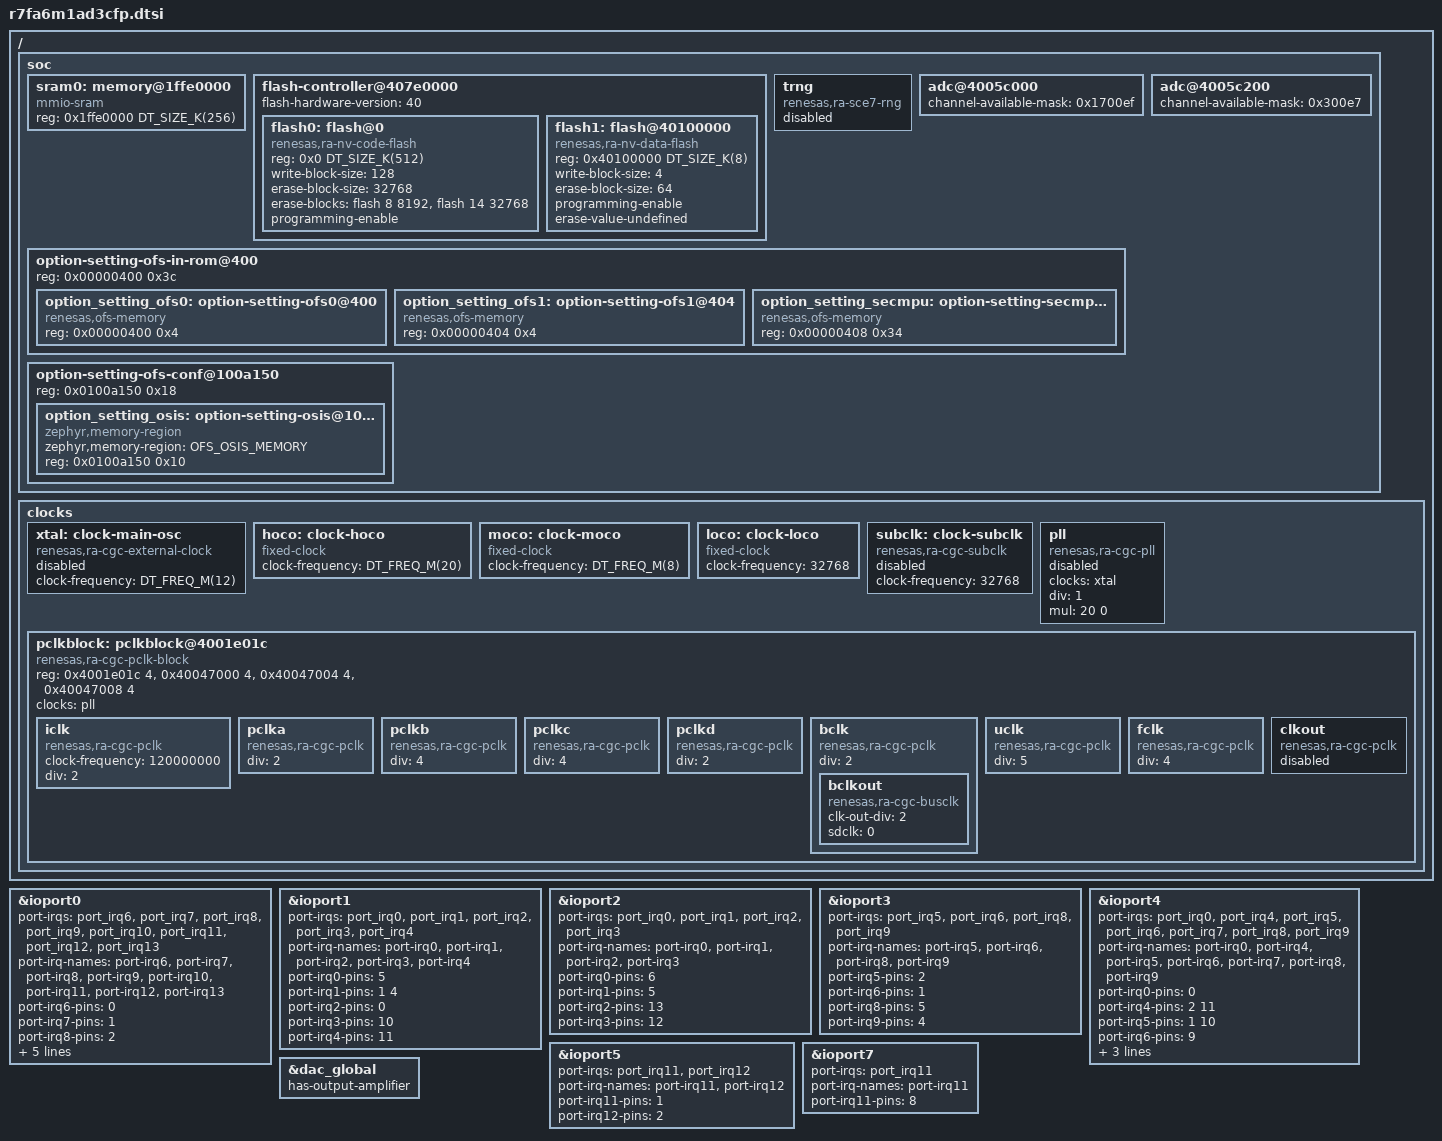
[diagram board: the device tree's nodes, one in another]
/*
 * Copyright (c) 2024-2025 Renesas Electronics Corporation
 *
 * SPDX-License-Identifier: Apache-2.0
 */

#include <zephyr/dt-bindings/clock/ra_clock.h>
#include <arm/renesas/ra/ra6/ra6-cm4-common.dtsi>
#include <zephyr/dt-bindings/misc/renesas/ra-elc/ra6m1-elc.h>

/delete-node/ &eth;
/delete-node/ &mdio;
/delete-node/ &qspi0;

/ {
	soc {
		sram0: memory@1ffe0000 {
			compatible = "mmio-sram";
			reg = <0x1ffe0000 DT_SIZE_K(256)>;
		};

		flash-controller@407e0000 {
			flash-hardware-version = <40>;
			#erase-block-cells = <2>;

			flash0: flash@0 {
				compatible = "renesas,ra-nv-code-flash";
				reg = <0x0 DT_SIZE_K(512)>;
				write-block-size = <128>;
				erase-block-size = <32768>;
				erase-blocks = <&flash 8 8192>, <&flash 14 32768>;
				programming-enable;
			};

			flash1: flash@40100000 {
				compatible = "renesas,ra-nv-data-flash";
				reg = <0x40100000 DT_SIZE_K(8)>;
				write-block-size = <4>;
				erase-block-size = <64>;
				programming-enable;
				erase-value-undefined;
			};
		};

		trng: trng {
			compatible = "renesas,ra-sce7-rng";
			status = "disabled";
		};

		adc@4005c000 {
			channel-available-mask = <0x1700ef>;
		};

		adc@4005c200 {
			channel-available-mask = <0x300e7>;
		};

		option-setting-ofs-in-rom@400 {
			reg = <0x00000400 0x3c>;
			#address-cells = <1>;
			#size-cells = <1>;

			option_setting_ofs0: option-setting-ofs0@400 {
				compatible = "renesas,ofs-memory";
				reg = <0x00000400 0x4>;
				status = "okay";
			};

			option_setting_ofs1: option-setting-ofs1@404 {
				compatible = "renesas,ofs-memory";
				reg = <0x00000404 0x4>;
				status = "okay";
			};

			option_setting_secmpu: option-setting-secmpu@408 {
				compatible = "renesas,ofs-memory";
				reg = <0x00000408 0x34>;
				status = "okay";
			};
		};

		option-setting-ofs-conf@100a150 {
			reg = <0x0100a150 0x18>;
			#address-cells = <1>;
			#size-cells = <1>;
			status = "okay";

			option_setting_osis: option-setting-osis@100a150 {
				compatible = "zephyr,memory-region";
				zephyr,memory-region = "OFS_OSIS_MEMORY";
				reg = <0x0100a150 0x10>;
				status = "okay";
			};
		};
	};

	clocks: clocks {
		#address-cells = <1>;
		#size-cells = <1>;

		xtal: clock-main-osc {
			compatible = "renesas,ra-cgc-external-clock";
			clock-frequency = <DT_FREQ_M(12)>;
			#clock-cells = <0>;
			status = "disabled";
		};

		hoco: clock-hoco {
			compatible = "fixed-clock";
			clock-frequency = <DT_FREQ_M(20)>;
			#clock-cells = <0>;
		};

		moco: clock-moco {
			compatible = "fixed-clock";
			clock-frequency = <DT_FREQ_M(8)>;
			#clock-cells = <0>;
		};

		loco: clock-loco {
			compatible = "fixed-clock";
			clock-frequency = <32768>;
			#clock-cells = <0>;
		};

		subclk: clock-subclk {
			compatible = "renesas,ra-cgc-subclk";
			clock-frequency = <32768>;
			#clock-cells = <0>;
			status = "disabled";
		};

		pll: pll {
			compatible = "renesas,ra-cgc-pll";
			#clock-cells = <0>;

			/* PLL */
			clocks = <&xtal>;
			div = <1>;
			mul = <20 0>;
			status = "disabled";
		};

		pclkblock: pclkblock@4001e01c {
			compatible = "renesas,ra-cgc-pclk-block";
			reg = <0x4001e01c 4>, <0x40047000 4>, <0x40047004 4>,
			      <0x40047008 4>;
			reg-names = "MSTPA", "MSTPB", "MSTPC",
				    "MSTPD";
			#clock-cells = <0>;
			clocks = <&pll>;
			status = "okay";

			iclk: iclk {
				compatible = "renesas,ra-cgc-pclk";
				clock-frequency = <120000000>;
				div = <2>;
				#clock-cells = <2>;
				status = "okay";
			};

			pclka: pclka {
				compatible = "renesas,ra-cgc-pclk";
				div = <2>;
				#clock-cells = <2>;
				status = "okay";
			};

			pclkb: pclkb {
				compatible = "renesas,ra-cgc-pclk";
				div = <4>;
				#clock-cells = <2>;
				status = "okay";
			};

			pclkc: pclkc {
				compatible = "renesas,ra-cgc-pclk";
				div = <4>;
				#clock-cells = <2>;
				status = "okay";
			};

			pclkd: pclkd {
				compatible = "renesas,ra-cgc-pclk";
				div = <2>;
				#clock-cells = <2>;
				status = "okay";
			};

			bclk: bclk {
				compatible = "renesas,ra-cgc-pclk";
				div = <2>;

				bclkout: bclkout {
					compatible = "renesas,ra-cgc-busclk";
					clk-out-div = <2>;
					sdclk = <0>;
					#clock-cells = <0>;
				};
				#clock-cells = <2>;
				status = "okay";
			};

			uclk: uclk {
				compatible = "renesas,ra-cgc-pclk";
				div = <5>;
				#clock-cells = <2>;
				status = "okay";
			};

			fclk: fclk {
				compatible = "renesas,ra-cgc-pclk";
				div = <4>;
				#clock-cells = <2>;
				status = "okay";
			};

			clkout: clkout {
				compatible = "renesas,ra-cgc-pclk";
				#clock-cells = <2>;
				status = "disabled";
			};
		};
	};
};

&ioport0 {
	port-irqs = <&port_irq6 &port_irq7 &port_irq8
		     &port_irq9 &port_irq10 &port_irq11
		     &port_irq12 &port_irq13>;
	port-irq-names = "port-irq6",
			 "port-irq7",
			 "port-irq8",
			 "port-irq9",
			 "port-irq10",
			 "port-irq11",
			 "port-irq12",
			 "port-irq13";
	port-irq6-pins = <0>;
	port-irq7-pins = <1>;
	port-irq8-pins = <2>;
	port-irq9-pins = <4>;
	port-irq10-pins = <5>;
	port-irq11-pins = <6>;
	port-irq12-pins = <8>;
	port-irq13-pins = <15>;
};

&ioport1 {
	port-irqs = <&port_irq0 &port_irq1 &port_irq2
		     &port_irq3 &port_irq4>;
	port-irq-names = "port-irq0",
			 "port-irq1",
			 "port-irq2",
			 "port-irq3",
			 "port-irq4";
	port-irq0-pins = <5>;
	port-irq1-pins = <1 4>;
	port-irq2-pins = <0>;
	port-irq3-pins = <10>;
	port-irq4-pins = <11>;
};

&ioport2 {
	port-irqs = <&port_irq0 &port_irq1 &port_irq2
		     &port_irq3>;
	port-irq-names = "port-irq0",
			 "port-irq1",
			 "port-irq2",
			 "port-irq3";
	port-irq0-pins = <6>;
	port-irq1-pins = <5>;
	port-irq2-pins = <13>;
	port-irq3-pins = <12>;
};

&ioport3 {
	port-irqs = <&port_irq5 &port_irq6
		     &port_irq8 &port_irq9>;
	port-irq-names = "port-irq5",
			 "port-irq6",
			 "port-irq8",
			 "port-irq9";
	port-irq5-pins = <2>;
	port-irq6-pins = <1>;
	port-irq8-pins = <5>;
	port-irq9-pins = <4>;
};

&ioport4 {
	port-irqs = <&port_irq0 &port_irq4 &port_irq5
		     &port_irq6 &port_irq7 &port_irq8
		     &port_irq9>;
	port-irq-names = "port-irq0",
			 "port-irq4",
			 "port-irq5",
			 "port-irq6",
			 "port-irq7",
			 "port-irq8",
			 "port-irq9";
	port-irq0-pins = <0>;
	port-irq4-pins = <2 11>;
	port-irq5-pins = <1 10>;
	port-irq6-pins = <9>;
	port-irq7-pins = <8>;
	port-irq8-pins = <15>;
	port-irq9-pins = <14>;
};

&ioport5 {
	port-irqs = <&port_irq11 &port_irq12>;
	port-irq-names = "port-irq11",
			 "port-irq12";
	port-irq11-pins = <1>;
	port-irq12-pins = <2>;
};

&ioport7 {
	port-irqs = <&port_irq11>;
	port-irq-names = "port-irq11";
	port-irq11-pins = <8>;
};

&dac_global {
	has-output-amplifier;
};
